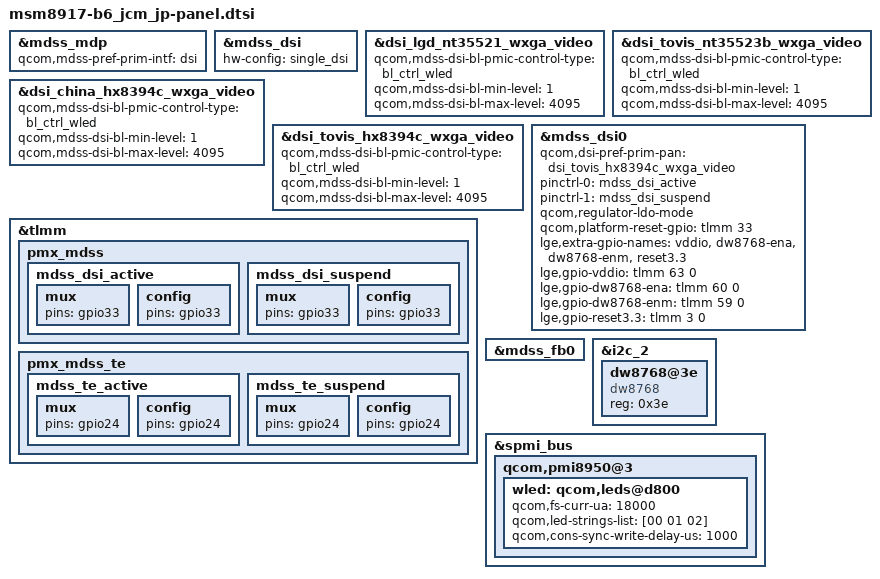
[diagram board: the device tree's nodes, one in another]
/*
 * Copyright (c) 2016, The Linux Foundation. All rights reserved.
 *
 * This program is free software; you can redistribute it and/or modify
 * it under the terms of the GNU General Public License version 2 and
 * only version 2 as published by the Free Software Foundation.
 *
 * This program is distributed in the hope that it will be useful,
 * but WITHOUT ANY WARRANTY; without even the implied warranty of
 * MERCHANTABILITY or FITNESS FOR A PARTICULAR PURPOSE.  See the
 * GNU General Public License for more details.
 */

#include "../dsi-panel-lgd-nt35521-wxga-video.dtsi"
#include "../dsi-panel-tovis-nt35523b-wxga-video.dtsi"
#include "../dsi-panel-china-hx8394c-wxga-video.dtsi"
#include "../dsi-panel-tovis-hx8394c-wxga-video.dtsi"


&wled {
	qcom,cons-sync-write-delay-us = <1000>;
};

&mdss_mdp {
	qcom,mdss-pref-prim-intf = "dsi";
};

&mdss_dsi {
	hw-config = "single_dsi";
};

&dsi_lgd_nt35521_wxga_video {
	qcom,mdss-dsi-bl-pmic-control-type = "bl_ctrl_wled";
	qcom,mdss-dsi-bl-min-level = <1>;
	qcom,mdss-dsi-bl-max-level = <4095>;
	/*qcom,panel-supply-entries = <&dsi_panel_pwr_supply>;*/
};

&dsi_tovis_nt35523b_wxga_video {
	qcom,mdss-dsi-bl-pmic-control-type = "bl_ctrl_wled";
	qcom,mdss-dsi-bl-min-level = <1>;
	qcom,mdss-dsi-bl-max-level = <4095>;
	/*qcom,panel-supply-entries = <&dsi_panel_pwr_supply>;*/
};

&dsi_china_hx8394c_wxga_video {
	qcom,mdss-dsi-bl-pmic-control-type = "bl_ctrl_wled";
	qcom,mdss-dsi-bl-min-level = <1>;
	qcom,mdss-dsi-bl-max-level = <4095>;
	/*qcom,panel-supply-entries = <&dsi_panel_pwr_supply>;*/
};

&dsi_tovis_hx8394c_wxga_video {
	qcom,mdss-dsi-bl-pmic-control-type = "bl_ctrl_wled";
	qcom,mdss-dsi-bl-min-level = <1>;
	qcom,mdss-dsi-bl-max-level = <4095>;
	/*qcom,panel-supply-entries = <&dsi_panel_pwr_supply>;*/
};


&tlmm {
	pmx_mdss {
		mdss_dsi_active: mdss_dsi_active {
			mux {
				pins = "gpio33";
			};

			config {
				pins = "gpio33";
			};
		};

		mdss_dsi_suspend: mdss_dsi_suspend {
			mux {
				pins = "gpio33";
			};

			config {
				pins = "gpio33";
			};
		};
	};

	pmx_mdss_te {
		mdss_te_active: mdss_te_active {
			mux {
				pins = "gpio24";
			};

			config {
				pins = "gpio24";
			};
		};

		mdss_te_suspend: mdss_te_suspend {
			mux {
				pins = "gpio24";
			};

			config {
				pins = "gpio24";
			};
		};
	};
};

&mdss_dsi0 {
	qcom,dsi-pref-prim-pan = <&dsi_tovis_hx8394c_wxga_video>;
	pinctrl-names = "mdss_default", "mdss_sleep";
	pinctrl-0 = <&mdss_dsi_active>;
	pinctrl-1 = <&mdss_dsi_suspend>;
	qcom,regulator-ldo-mode;
	qcom,platform-reset-gpio = <&tlmm 33 0>;

	lge,extra-gpio-names = "vddio", "dw8768-ena", "dw8768-enm", "reset3.3";

	lge,gpio-vddio = <&tlmm 63 0>;
	lge,gpio-dw8768-ena = <&tlmm 60 0>;
	lge,gpio-dw8768-enm = <&tlmm 59 0>;
	lge,gpio-reset3.3 = <&tlmm 3 0>;

	/delete-property/ vdd-supply;
	/delete-property/ vddio-supply;

	/*lab-supply = <&lab_regulator>;
	ibb-supply = <&ibb_regulator>;*/
};
/*
&labibb {
	status = "ok";
	qpnp,qpnp-labibb-mode = "lcd";
};

&lab_regulator {
	qcom,qpnp-lab-init-lcd-voltage = <5200000>;
};

&ibb_regulator {
	qcom,qpnp-ibb-init-lcd-voltage = <5200000>;
	qcom,qpnp-ibb-discharge-resistor = <32>;
	qcom,qpnp-ibb-lab-pwrup-delay = <2000>;
	qcom,qpnp-ibb-lab-pwrdn-delay = <1000>;
};

&soc {
	dsi_panel_pwr_supply: dsi_panel_pwr_supply {
		qcom,panel-supply-entry@0 {
			reg = <2>;
			qcom,supply-name = "lab";
			qcom,supply-min-voltage = <4600000>;
			qcom,supply-max-voltage = <6000000>;
			qcom,supply-enable-load = <100000>;
			qcom,supply-disable-load = <100>;
		};

		qcom,panel-supply-entry@1 {
			reg = <3>;
			qcom,supply-name = "ibb";
			qcom,supply-min-voltage = <4600000>;
			qcom,supply-max-voltage = <6000000>;
			qcom,supply-enable-load = <100000>;
			qcom,supply-disable-load = <100>;
			qcom,supply-post-on-sleep = <20>;
		};
	};
};
*/
&mdss_fb0 {
	/delete-property/ qcom,mdss-fb-splash-logo-enabled;
};

&i2c_2 {
     dw8768@3e {
         status = "ok";
         compatible = "dw8768";
         reg = <0x3e>;
    };
};

&spmi_bus {
	qcom,pmi8950@3 {
		wled: qcom,leds@d800 {
			qcom,fs-curr-ua = <18000>;
			qcom,led-strings-list = [00 01 02];
		};
	};
};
